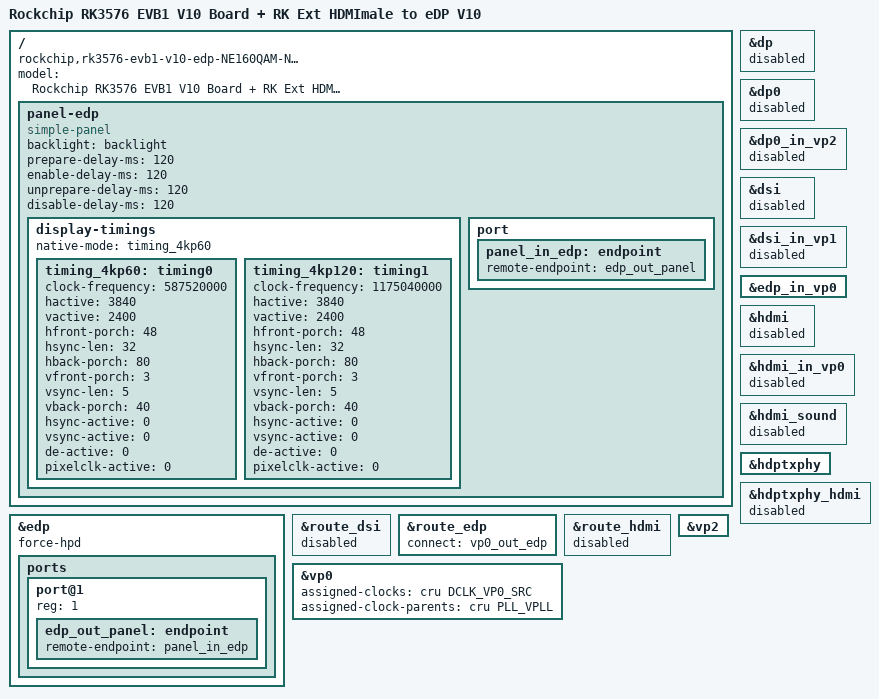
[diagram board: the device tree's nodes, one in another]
// SPDX-License-Identifier: (GPL-2.0+ OR MIT)
/*
 * Copyright (c) 2025 Rockchip Electronics Co., Ltd.
 *
 */

/dts-v1/;

#include "rk3576.dtsi"
#include "rk3576-evb1.dtsi"
#include "rk3576-evb1-cam-dcphy0.dtsi"
#include "rk3576-android.dtsi"

/ {
	model = "Rockchip RK3576 EVB1 V10 Board + RK Ext HDMImale to eDP V10";
	compatible = "rockchip,rk3576-evb1-v10-edp-NE160QAM-NX1", "rockchip,rk3576";

	panel-edp {
		compatible = "simple-panel";
		backlight = <&backlight>;
		prepare-delay-ms = <120>;
		enable-delay-ms = <120>;
		unprepare-delay-ms = <120>;
		disable-delay-ms = <120>;

		display-timings {
			native-mode = <&timing_4kp60>;
			timing_4kp60: timing0 {
				clock-frequency = <587520000>;
				hactive = <3840>;
				vactive = <2400>;
				hfront-porch = <48>;
				hsync-len = <32>;
				hback-porch = <80>;
				vfront-porch = <3>;
				vsync-len = <5>;
				vback-porch = <40>;
				hsync-active = <0>;
				vsync-active = <0>;
				de-active = <0>;
				pixelclk-active = <0>;
			};

			timing_4kp120: timing1 {
				clock-frequency = <1175040000>;
				hactive = <3840>;
				vactive = <2400>;
				hfront-porch = <48>;
				hsync-len = <32>;
				hback-porch = <80>;
				vfront-porch = <3>;
				vsync-len = <5>;
				vback-porch = <40>;
				hsync-active = <0>;
				vsync-active = <0>;
				de-active = <0>;
				pixelclk-active = <0>;
			};
		};

		port {
			panel_in_edp: endpoint {
				remote-endpoint = <&edp_out_panel>;
			};
		};
	};
};

&dp {
	status = "disabled";
};

&dp0 {
	status = "disabled";
};

&dp0_in_vp2 {
	status = "disabled";
};

&dsi {
	status = "disabled";
};

&dsi_in_vp1 {
	status = "disabled";
};

&edp {
	force-hpd;
	status = "okay";

	ports {
		port@1 {
			reg = <1>;

			edp_out_panel: endpoint {
				remote-endpoint = <&panel_in_edp>;
			};
		};
	};
};

&edp_in_vp0 {
	status = "okay";
};

&hdmi {
	status = "disabled";
};

&hdmi_in_vp0 {
	status = "disabled";
};

&hdmi_sound {
	status = "disabled";
};

&hdptxphy {
	status = "okay";
};

&hdptxphy_hdmi {
	status = "disabled";
};

&route_dsi {
	status = "disabled";
};

&route_edp {
	status = "okay";
	connect = <&vp0_out_edp>;
};

&route_hdmi {
	status = "disabled";
};

&vp0 {
	assigned-clocks = <&cru DCLK_VP0_SRC>;
	assigned-clock-parents = <&cru PLL_VPLL>;
};

&vp2 {
	/delete-property/ assigned-clocks;
	/delete-property/ assigned-clock-parents;
};
